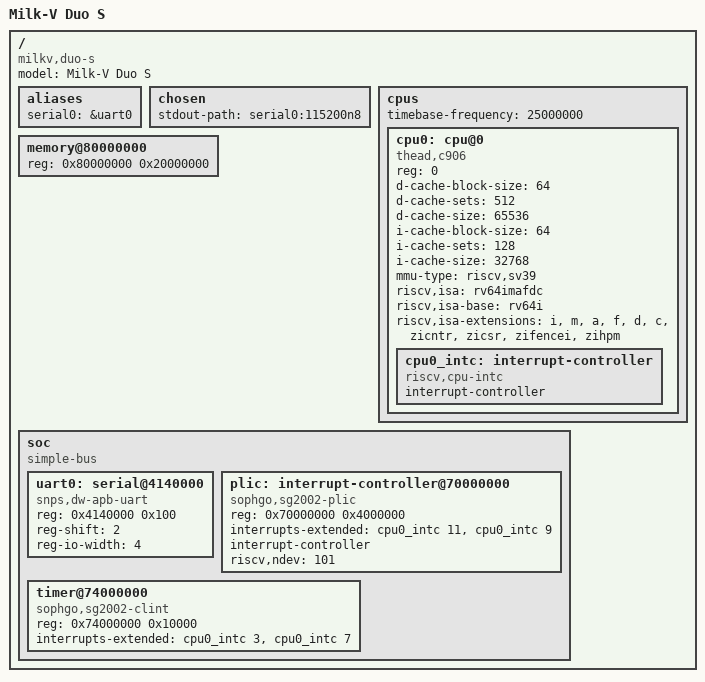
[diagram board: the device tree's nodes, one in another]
// SPDX-License-Identifier: (GPL-2.0 OR MIT)
/*
 * Device tree embedded in OpenSBI (FW_FDT_PATH) for the SG2000 C906 core.
 *
 * Only what OpenSBI's generic platform reads: the root compatible (thead-generic
 * override, C9xx PMU quirk), the hart and its ISA, the console UART, the CLINT
 * (mtimer + mswi) and the PLIC. OpenSBI adds its own reserved-memory node at
 * runtime. U-Boot (OF_EMBED) and Linux (FIT) bring their own device trees.
 */

/dts-v1/;

/ {
	#address-cells = <1>;
	#size-cells = <1>;
	compatible = "milkv,duo-s", "sophgo,sg2002";
	model = "Milk-V Duo S";

	aliases {
		serial0 = &uart0;
	};

	chosen {
		stdout-path = "serial0:115200n8";
	};

	cpus {
		#address-cells = <1>;
		#size-cells = <0>;
		timebase-frequency = <25000000>;

		cpu0: cpu@0 {
			compatible = "thead,c906", "riscv";
			device_type = "cpu";
			reg = <0>;
			d-cache-block-size = <64>;
			d-cache-sets = <512>;
			d-cache-size = <65536>;
			i-cache-block-size = <64>;
			i-cache-sets = <128>;
			i-cache-size = <32768>;
			mmu-type = "riscv,sv39";
			riscv,isa = "rv64imafdc";
			riscv,isa-base = "rv64i";
			riscv,isa-extensions = "i", "m", "a", "f", "d", "c", "zicntr", "zicsr",
					       "zifencei", "zihpm";

			cpu0_intc: interrupt-controller {
				compatible = "riscv,cpu-intc";
				interrupt-controller;
				#interrupt-cells = <1>;
			};
		};
	};

	memory@80000000 {
		device_type = "memory";
		reg = <0x80000000 0x20000000>;
	};

	soc {
		compatible = "simple-bus";
		#address-cells = <1>;
		#size-cells = <1>;
		ranges;

		/* No clock-frequency: OpenSBI keeps the divisor the FSBL programmed. */
		uart0: serial@4140000 {
			compatible = "snps,dw-apb-uart";
			reg = <0x4140000 0x100>;
			reg-shift = <2>;
			reg-io-width = <4>;
		};

		/* Contexts: M-mode external (11), S-mode external (9). */
		plic: interrupt-controller@70000000 {
			compatible = "sophgo,sg2002-plic", "thead,c900-plic";
			reg = <0x70000000 0x4000000>;
			interrupts-extended = <&cpu0_intc 11>, <&cpu0_intc 9>;
			interrupt-controller;
			#address-cells = <0>;
			#interrupt-cells = <2>;
			riscv,ndev = <101>;
		};

		/* M-mode software (3) and timer (7) interrupts. */
		timer@74000000 {
			compatible = "sophgo,sg2002-clint", "thead,c900-clint";
			reg = <0x74000000 0x10000>;
			interrupts-extended = <&cpu0_intc 3>, <&cpu0_intc 7>;
		};
	};
};
